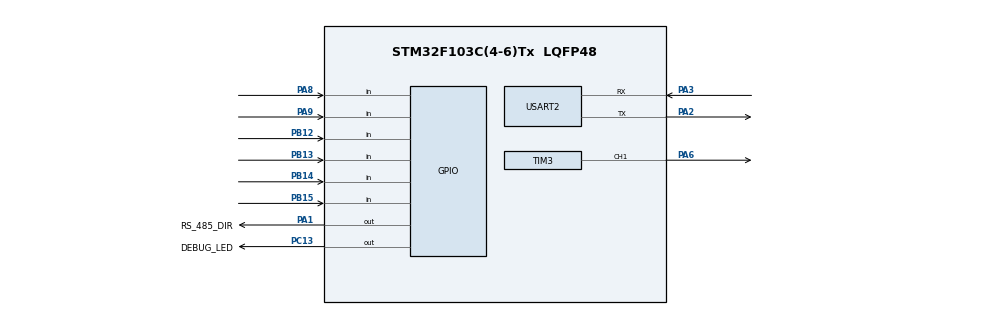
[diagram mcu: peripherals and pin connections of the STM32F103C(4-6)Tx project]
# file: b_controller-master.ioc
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Mcu.Family=STM32F1
Mcu.Name=STM32F103C(4-6)Tx
Mcu.Package=LQFP48
NVIC.PriorityGroup=NVIC_PRIORITYGROUP_4
NVIC.RCC_IRQn=true\:0\:0\:false\:false\:true\:true\:false
NVIC.USART2_IRQn=true\:0\:0\:false\:false\:true\:true\:true
PA1.GPIO_Label=RS_485_DIR
PA1.Signal=GPIO_Output
PA13.Mode=Serial_Wire
PA13.Signal=SYS_JTMS-SWDIO
PA14.Mode=Serial_Wire
PA14.Signal=SYS_JTCK-SWCLK
PA2.Mode=Asynchronous
PA2.Signal=USART2_TX
PA3.Mode=Asynchronous
PA3.Signal=USART2_RX
PA6.Signal=S_TIM3_CH1
PA8.GPIO_PuPd=GPIO_PULLDOWN
PA8.Signal=GPIO_Input
PA9.GPIO_PuPd=GPIO_PULLDOWN
PA9.Signal=GPIO_Input
PB12.GPIO_PuPd=GPIO_PULLDOWN
PB12.Signal=GPIO_Input
PB13.GPIO_PuPd=GPIO_PULLDOWN
PB13.Signal=GPIO_Input
PB14.GPIO_PuPd=GPIO_PULLDOWN
PB14.Signal=GPIO_Input
PB15.GPIO_PuPd=GPIO_PULLDOWN
PB15.Signal=GPIO_Input
PC13-TAMPER-RTC.GPIO_Label=DEBUG_LED
PC13-TAMPER-RTC.Signal=GPIO_Output
PD0-OSC_IN.Mode=HSE-External-Oscillator
PD0-OSC_IN.Signal=RCC_OSC_IN
PD1-OSC_OUT.Mode=HSE-External-Oscillator
PD1-OSC_OUT.Signal=RCC_OSC_OUT
ProjectManager.HeapSize=0x200
ProjectManager.StackSize=0x400
ProjectManager.TargetToolchain=STM32CubeIDE
RCC.APB1Freq_Value=8000000
RCC.APB2Freq_Value=8000000
SH.S_TIM3_CH1.0=TIM3_CH1,PWM Generation1 CH1
TIM3.Channel-PWM\ Generation1\ CH1=TIM_CHANNEL_1
TIM3.Period=60000
TIM3.Prescaler=23
USART2.VirtualMode=VM_ASYNC
VP_TIM3_VS_ClockSourceINT.Mode=Internal
board=custom

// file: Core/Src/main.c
/* USER CODE BEGIN Header */
/**
 ******************************************************************************
 * @file           : main.c
 * @brief          : Main program body
 ******************************************************************************
 * @attention
 *
 * <h2><center>&copy; Copyright (c) 2020 STMicroelectronics.
 * All rights reserved.</center></h2>
 *
 * This software component is licensed by ST under BSD 3-Clause license,
 * the "License"; You may not use this file except in compliance with the
 * License. You may obtain a copy of the License at:
 *                        opensource.org/licenses/BSD-3-Clause
 *
 ******************************************************************************
 */
/* USER CODE END Header */
#include "main.h"

TIM_HandleTypeDef htim3;

UART_HandleTypeDef huart2;

/* USER CODE BEGIN PV */
extern esc_settings esc_struct;
uint8_t rx_flag = 0;
uint8_t rx_array[RECEIVE_BUFFER_SIZE] = { 0 };
/* USER CODE END PV */

void SystemClock_Config(void);
static void MX_GPIO_Init(void);
static void MX_USART2_UART_Init(void);
static void MX_TIM3_Init(void);

int main(void) {

	/* MCU Configuration--------------------------------------------------------*/

	/* Reset of all peripherals, Initializes the Flash interface and the Systick. */
	HAL_Init();

	/* Configure the system clock */
	SystemClock_Config();

	/* Initialize all configured peripherals */
	MX_GPIO_Init();
	MX_USART2_UART_Init();
	MX_TIM3_Init();
	/* USER CODE BEGIN 2 */
	HAL_GPIO_WritePin(RS_485_DIR_GPIO_Port, RS_485_DIR_Pin, RESET);
	HAL_GPIO_WritePin(DEBUG_LED_GPIO_Port, DEBUG_LED_Pin, RESET);
	HAL_TIM_PWM_Start(&htim3, TIM_CHANNEL_1);

	esc_struct.PWM_duty = 0;
	update_esc_settings(&esc_struct);
	HAL_Delay(3000);

	HAL_UART_Receive_IT(&huart2, rx_array, 1);
	/* USER CODE END 2 */

	/* Infinite loop */
	while (1) {

	}
}
	/**
	 * @brief System Clock Configuration
	 * @retval None
	 */
	void SystemClock_Config(void) {
		RCC_OscInitTypeDef RCC_OscInitStruct = { 0 };
		RCC_ClkInitTypeDef RCC_ClkInitStruct = { 0 };

		/** Initializes the RCC Oscillators according to the specified parameters
		 * in the RCC_OscInitTypeDef structure.
		 */
		RCC_OscInitStruct.OscillatorType = RCC_OSCILLATORTYPE_HSI;
		RCC_OscInitStruct.HSIState = RCC_HSI_ON;
		RCC_OscInitStruct.HSICalibrationValue = RCC_HSICALIBRATION_DEFAULT;
		RCC_OscInitStruct.PLL.PLLState = RCC_PLL_NONE;
		if (HAL_RCC_OscConfig(&RCC_OscInitStruct) != HAL_OK) {
			Error_Handler();
		}
		/** Initializes the CPU, AHB and APB buses clocks
		 */
		RCC_ClkInitStruct.ClockType = RCC_CLOCKTYPE_HCLK | RCC_CLOCKTYPE_SYSCLK
				| RCC_CLOCKTYPE_PCLK1 | RCC_CLOCKTYPE_PCLK2;
		RCC_ClkInitStruct.SYSCLKSource = RCC_SYSCLKSOURCE_HSI;
		RCC_ClkInitStruct.AHBCLKDivider = RCC_SYSCLK_DIV1;
		RCC_ClkInitStruct.APB1CLKDivider = RCC_HCLK_DIV1;
		RCC_ClkInitStruct.APB2CLKDivider = RCC_HCLK_DIV1;

		if (HAL_RCC_ClockConfig(&RCC_ClkInitStruct, FLASH_LATENCY_0)
				!= HAL_OK) {
			Error_Handler();
		}
	}
	/**
	 * @brief TIM3 Initialization Function
	 * @param None
	 * @retval None
	 */
	static void MX_TIM3_Init(void) {

		TIM_ClockConfigTypeDef sClockSourceConfig = { 0 };
		TIM_MasterConfigTypeDef sMasterConfig = { 0 };
		TIM_OC_InitTypeDef sConfigOC = { 0 };

		htim3.Instance = TIM3;
		htim3.Init.Prescaler = 23;
		htim3.Init.CounterMode = TIM_COUNTERMODE_UP;
		htim3.Init.Period = 60000;
		htim3.Init.ClockDivision = TIM_CLOCKDIVISION_DIV1;
		htim3.Init.AutoReloadPreload = TIM_AUTORELOAD_PRELOAD_DISABLE;
		if (HAL_TIM_Base_Init(&htim3) != HAL_OK) {
			Error_Handler();
		}
		sClockSourceConfig.ClockSource = TIM_CLOCKSOURCE_INTERNAL;
		if (HAL_TIM_ConfigClockSource(&htim3, &sClockSourceConfig) != HAL_OK) {
			Error_Handler();
		}
		if (HAL_TIM_PWM_Init(&htim3) != HAL_OK) {
			Error_Handler();
		}
		sMasterConfig.MasterOutputTrigger = TIM_TRGO_RESET;
		sMasterConfig.MasterSlaveMode = TIM_MASTERSLAVEMODE_DISABLE;
		if (HAL_TIMEx_MasterConfigSynchronization(&htim3, &sMasterConfig)
				!= HAL_OK) {
			Error_Handler();
		}
		sConfigOC.OCMode = TIM_OCMODE_PWM1;
		sConfigOC.Pulse = 0;
		sConfigOC.OCPolarity = TIM_OCPOLARITY_HIGH;
		sConfigOC.OCFastMode = TIM_OCFAST_DISABLE;
		if (HAL_TIM_PWM_ConfigChannel(&htim3, &sConfigOC, TIM_CHANNEL_1)
				!= HAL_OK) {
			Error_Handler();
		}
		HAL_TIM_MspPostInit(&htim3);

	}

	/**
	 * @brief USART2 Initialization Function
	 * @param None
	 * @retval None
	 */
	static void MX_USART2_UART_Init(void) {

		huart2.Instance = USART2;
		huart2.Init.BaudRate = 115200;
		huart2.Init.WordLength = UART_WORDLENGTH_8B;
		huart2.Init.StopBits = UART_STOPBITS_1;
		huart2.Init.Parity = UART_PARITY_NONE;
		huart2.Init.Mode = UART_MODE_TX_RX;
		huart2.Init.HwFlowCtl = UART_HWCONTROL_NONE;
		huart2.Init.OverSampling = UART_OVERSAMPLING_16;
		if (HAL_UART_Init(&huart2) != HAL_OK) {
			Error_Handler();
		}

	}

	/**
	 * @brief GPIO Initialization Function
	 * @param None
	 * @retval None
	 */
	static void MX_GPIO_Init(void) {
		GPIO_InitTypeDef GPIO_InitStruct = { 0 };

		/* GPIO Ports Clock Enable */
		__HAL_RCC_GPIOC_CLK_ENABLE();
		__HAL_RCC_GPIOD_CLK_ENABLE();
		__HAL_RCC_GPIOA_CLK_ENABLE();
		__HAL_RCC_GPIOB_CLK_ENABLE();

		/*Configure GPIO pin Output Level */
		HAL_GPIO_WritePin(DEBUG_LED_GPIO_Port, DEBUG_LED_Pin, GPIO_PIN_RESET);

		/*Configure GPIO pin Output Level */
		HAL_GPIO_WritePin(RS_485_DIR_GPIO_Port, RS_485_DIR_Pin, GPIO_PIN_RESET);

		/*Configure GPIO pin : DEBUG_LED_Pin */
		GPIO_InitStruct.Pin = DEBUG_LED_Pin;
		GPIO_InitStruct.Mode = GPIO_MODE_OUTPUT_PP;
		GPIO_InitStruct.Pull = GPIO_NOPULL;
		GPIO_InitStruct.Speed = GPIO_SPEED_FREQ_LOW;
		HAL_GPIO_Init(DEBUG_LED_GPIO_Port, &GPIO_InitStruct);

		/*Configure GPIO pin : RS_485_DIR_Pin */
		GPIO_InitStruct.Pin = RS_485_DIR_Pin;
		GPIO_InitStruct.Mode = GPIO_MODE_OUTPUT_PP;
		GPIO_InitStruct.Pull = GPIO_NOPULL;
		GPIO_InitStruct.Speed = GPIO_SPEED_FREQ_LOW;
		HAL_GPIO_Init(RS_485_DIR_GPIO_Port, &GPIO_InitStruct);

		/*Configure GPIO pins : PB12 PB13 PB14 PB15 */
		GPIO_InitStruct.Pin = GPIO_PIN_12 | GPIO_PIN_13 | GPIO_PIN_14
				| GPIO_PIN_15;
		GPIO_InitStruct.Mode = GPIO_MODE_INPUT;
		GPIO_InitStruct.Pull = GPIO_PULLDOWN;
		HAL_GPIO_Init(GPIOB, &GPIO_InitStruct);

		/*Configure GPIO pins : PA8 PA9 */
		GPIO_InitStruct.Pin = GPIO_PIN_8 | GPIO_PIN_9;
		GPIO_InitStruct.Mode = GPIO_MODE_INPUT;
		GPIO_InitStruct.Pull = GPIO_PULLDOWN;
		HAL_GPIO_Init(GPIOA, &GPIO_InitStruct);

	}

	/**
	 * @brief  This function is executed in case of error occurrence.
	 * @retval None
	 */
	void Error_Handler(void) {
	}

	/************************ (C) COPYRIGHT STMicroelectronics *****END OF FILE****/
